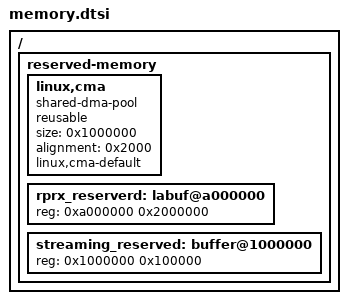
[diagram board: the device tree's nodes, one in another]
/*
 * define memory for DMA pool
 */

/ {
	reserved-memory {
		#address-cells = <1>;
		#size-cells = <1>;
		ranges;
		linux,cma {
			compatible = "shared-dma-pool";
			reusable;
			size = <0x1000000>;
			alignment = <0x2000>;
			linux,cma-default;
		};
		rprx_reserverd: labuf@a000000 {
			/*compatible = "redpitaya,rprx-memory";*/
			reg = <0xa000000 0x2000000>;
		};

		streaming_reserved: buffer@1000000 {
			reg = <0x1000000 0x100000>;
		};

	};
};
